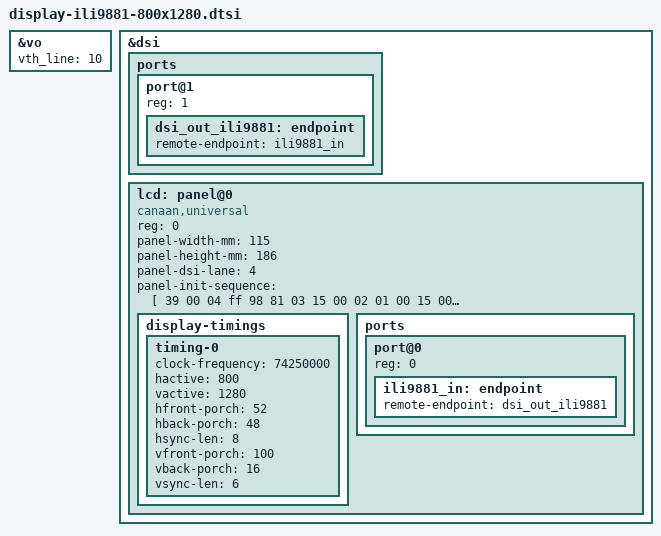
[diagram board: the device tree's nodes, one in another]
// SPDX-License-Identifier: GPL-2.0
&vo {
	vth_line = <10>;
};

&dsi {
	ports {
		port@1 {
			reg = <1>;
			dsi_out_ili9881: endpoint {
				remote-endpoint = <&ili9881_in>;
			};
		};
	};

	lcd: panel@0 {
		compatible = "canaan,universal";
		reg = <0>;

		panel-width-mm = <115>;
		panel-height-mm = <186>;
		panel-dsi-lane = <4>;

		panel-init-sequence = [
			39 00 04 ff 98 81 03
			15 00 02 01 00
			15 00 02 02 00
			15 00 02 03 53
			15 00 02 04 13
			15 00 02 05 00
			15 00 02 06 04
			15 00 02 07 00
			15 00 02 08 00
			15 00 02 09 22
			15 00 02 0a 22
			15 00 02 0b 00
			15 00 02 0c 01
			15 00 02 0d 00
			15 00 02 0e 00
			15 00 02 0f 25
			15 00 02 10 25
			15 00 02 11 00
			15 00 02 12 00
			15 00 02 13 00
			15 00 02 14 00
			15 00 02 15 00
			15 00 02 16 00
			15 00 02 17 00
			15 00 02 18 00
			15 00 02 19 00
			15 00 02 1a 00
			15 00 02 1b 00
			15 00 02 1c 00
			15 00 02 1d 00
			15 00 02 1e 44
			15 00 02 1f 80
			15 00 02 20 02
			15 00 02 21 03
			15 00 02 22 00
			15 00 02 23 00
			15 00 02 24 00
			15 00 02 25 00
			15 00 02 26 00
			15 00 02 27 00
			15 00 02 28 33
			15 00 02 29 03
			15 00 02 2a 00
			15 00 02 2b 00
			15 00 02 2c 00
			15 00 02 2d 00
			15 00 02 2e 00
			15 00 02 2f 00
			15 00 02 30 00
			15 00 02 31 00
			15 00 02 32 00
			15 00 02 33 00
			15 00 02 34 04
			15 00 02 35 00
			15 00 02 36 00
			15 00 02 37 00
			15 00 02 38 3c
			15 00 02 39 00
			15 00 02 3a 40
			15 00 02 3b 40
			15 00 02 3c 00
			15 00 02 3d 00
			15 00 02 3e 00
			15 00 02 3f 00
			15 00 02 40 00
			15 00 02 41 00
			15 00 02 42 00
			15 00 02 43 00
			15 00 02 44 00
			15 00 02 50 01
			15 00 02 51 23
			15 00 02 52 45
			15 00 02 53 67
			15 00 02 54 89
			15 00 02 55 ab
			15 00 02 56 01
			15 00 02 57 23
			15 00 02 58 45
			15 00 02 59 67
			15 00 02 5a 89
			15 00 02 5b ab
			15 00 02 5c cd
			15 00 02 5d ef
			15 00 02 5e 11
			15 00 02 5f 01
			15 00 02 60 00
			15 00 02 61 15
			15 00 02 62 14
			15 00 02 63 0c
			15 00 02 64 0d
			15 00 02 65 0e
			15 00 02 66 0f
			15 00 02 67 06
			15 00 02 68 02
			15 00 02 69 02
			15 00 02 6a 02
			15 00 02 6b 02
			15 00 02 6c 02
			15 00 02 6d 02
			15 00 02 6e 08
			15 00 02 6f 02
			15 00 02 70 02
			15 00 02 71 02
			15 00 02 72 02
			15 00 02 73 02
			15 00 02 74 02
			15 00 02 75 01
			15 00 02 76 00
			15 00 02 77 15
			15 00 02 78 14
			15 00 02 79 0c
			15 00 02 7a 0d
			15 00 02 7b 0e
			15 00 02 7c 0f
			15 00 02 7d 08
			15 00 02 7e 02
			15 00 02 7f 02
			15 00 02 80 02
			15 00 02 81 02
			15 00 02 82 02
			15 00 02 83 02
			15 00 02 84 06
			15 00 02 85 02
			15 00 02 86 02
			15 00 02 87 02
			15 00 02 88 02
			15 00 02 89 02
			15 00 02 8a 02
			39 00 04 ff 98 81 04
			15 00 02 6c 15
			15 00 02 6e 3b
			15 00 02 6f 55
			15 00 02 8d 14
			15 00 02 87 ba
			15 00 02 26 76
			15 00 02 b2 d1
			15 00 02 3b 98
			15 00 02 35 1f
			15 00 02 3A 24
			15 00 02 b5 27
			15 00 02 31 75
			15 00 02 30 03
			15 00 02 33 14
			15 00 02 38 02
			15 00 02 39 00
			15 00 02 7a 10
			39 00 04 ff 98 81 01
			15 00 02 22 0a
			15 00 02 31 0a
			15 00 02 50 ae
			15 00 02 51 a9
			15 00 02 60 1f
			15 00 02 62 07
			15 00 02 63 00
			15 00 02 52 00
			15 00 02 53 56
			15 00 02 54 00
			15 00 02 55 59
			15 00 02 a0 08
			15 00 02 a1 20
			15 00 02 a2 2d
			15 00 02 a3 13
			15 00 02 a4 16
			15 00 02 a5 29
			15 00 02 a6 1d
			15 00 02 a7 1e
			15 00 02 a8 77
			15 00 02 a9 17
			15 00 02 aa 24
			15 00 02 ab 6a
			15 00 02 ac 22
			15 00 02 ad 24
			15 00 02 ae 5a
			15 00 02 af 2b
			15 00 02 b0 2c
			15 00 02 b1 4d
			15 00 02 b2 6f
			15 00 02 b3 3f
			15 00 02 c0 08
			15 00 02 c1 1e
			15 00 02 c2 2b
			15 00 02 c3 13
			15 00 02 c4 16
			15 00 02 c5 28
			15 00 02 c6 1a
			15 00 02 c7 1d
			15 00 02 c8 75
			15 00 02 c9 18
			15 00 02 ca 25
			15 00 02 cb 71
			15 00 02 cc 23
			15 00 02 cd 28
			15 00 02 ce 59
			15 00 02 cf 2c
			15 00 02 d0 30
			15 00 02 d1 55
			15 00 02 d2 6b
			15 00 02 d3 3f
			39 00 04 ff 98 81 00
			05 00 01 35
			05 78 01 11
			05 00 01 29
		];

		display-timings {
			timing-0 {
				clock-frequency = <74250000>;
				hactive = <800>;
				vactive = <1280>;
				hfront-porch = <52>;
				hback-porch = <48>;
				hsync-len = <8>;
				vfront-porch = <100>;
				vback-porch = <16>;
				vsync-len = <6>;
			};
		};

		ports {
			#address-cells = <1>;
			#size-cells = <0>;

			port@0 {
				reg = <0>;
				ili9881_in: endpoint {
					remote-endpoint = <&dsi_out_ili9881>;
				};
			};
		};
	};
};
